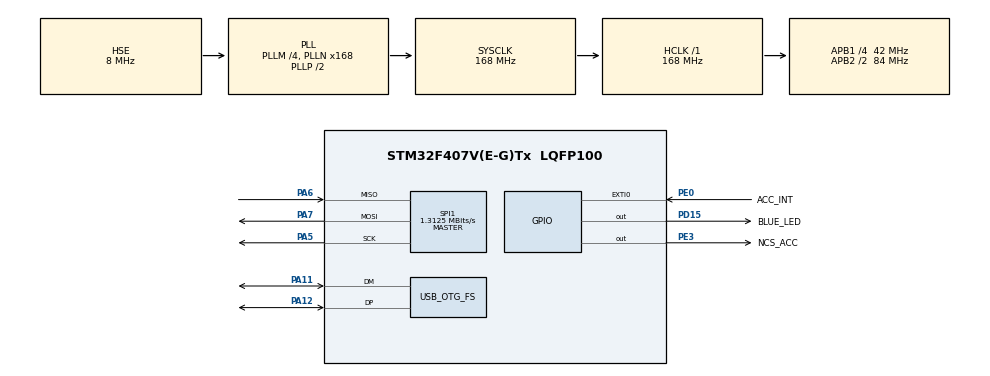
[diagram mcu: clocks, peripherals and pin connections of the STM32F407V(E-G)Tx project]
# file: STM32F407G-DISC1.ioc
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Dma.Request0=SPI1_RX
Dma.Request1=SPI1_TX
Dma.SPI1_RX.0.Direction=DMA_PERIPH_TO_MEMORY
Dma.SPI1_RX.0.FIFOMode=DMA_FIFOMODE_DISABLE
Dma.SPI1_RX.0.Instance=DMA2_Stream0
Dma.SPI1_RX.0.MemDataAlignment=DMA_MDATAALIGN_BYTE
Dma.SPI1_RX.0.MemInc=DMA_MINC_ENABLE
Dma.SPI1_RX.0.Mode=DMA_NORMAL
Dma.SPI1_RX.0.PeriphDataAlignment=DMA_PDATAALIGN_BYTE
Dma.SPI1_RX.0.PeriphInc=DMA_PINC_DISABLE
Dma.SPI1_RX.0.Priority=DMA_PRIORITY_HIGH
Dma.SPI1_TX.1.Direction=DMA_MEMORY_TO_PERIPH
Dma.SPI1_TX.1.FIFOMode=DMA_FIFOMODE_DISABLE
Dma.SPI1_TX.1.Instance=DMA2_Stream3
Dma.SPI1_TX.1.MemDataAlignment=DMA_MDATAALIGN_BYTE
Dma.SPI1_TX.1.MemInc=DMA_MINC_ENABLE
Dma.SPI1_TX.1.Mode=DMA_NORMAL
Dma.SPI1_TX.1.PeriphDataAlignment=DMA_PDATAALIGN_BYTE
Dma.SPI1_TX.1.PeriphInc=DMA_PINC_DISABLE
Dma.SPI1_TX.1.Priority=DMA_PRIORITY_HIGH
Mcu.Family=STM32F4
Mcu.Name=STM32F407V(E-G)Tx
Mcu.Package=LQFP100
NVIC.DMA2_Stream0_IRQn=true\:0\:0\:false\:false\:true\:false\:true
NVIC.DMA2_Stream3_IRQn=true\:0\:0\:false\:false\:true\:false\:true
NVIC.EXTI0_IRQn=true\:0\:0\:false\:false\:true\:true\:true
NVIC.OTG_FS_IRQn=true\:0\:0\:false\:false\:true\:false\:true
NVIC.PriorityGroup=NVIC_PRIORITYGROUP_4
PA11.Mode=Device_Only
PA11.Signal=USB_OTG_FS_DM
PA12.Mode=Device_Only
PA12.Signal=USB_OTG_FS_DP
PA13.Mode=Trace_Asynchronous_SW
PA13.Signal=SYS_JTMS-SWDIO
PA14.Mode=Trace_Asynchronous_SW
PA14.Signal=SYS_JTCK-SWCLK
PA5.Mode=Full_Duplex_Master
PA5.Signal=SPI1_SCK
PA6.Mode=Full_Duplex_Master
PA6.Signal=SPI1_MISO
PA7.Mode=Full_Duplex_Master
PA7.Signal=SPI1_MOSI
PB3.Mode=Trace_Asynchronous_SW
PB3.Signal=SYS_JTDO-SWO
PD15.GPIO_Label=BLUE_LED
PD15.Signal=GPIO_Output
PE0.GPIO_Label=ACC_INT
PE0.Signal=GPXTI0
PE3.GPIO_Label=NCS_ACC
PE3.Signal=GPIO_Output
PH0-OSC_IN.Mode=HSE-External-Oscillator
PH0-OSC_IN.Signal=RCC_OSC_IN
PH1-OSC_OUT.Mode=HSE-External-Oscillator
PH1-OSC_OUT.Signal=RCC_OSC_OUT
ProjectManager.HeapSize=0x200
ProjectManager.StackSize=0x400
ProjectManager.TargetToolchain=STM32CubeIDE
RCC.48MHZClocksFreq_Value=48000000
RCC.AHBFreq_Value=168000000
RCC.APB1CLKDivider=RCC_HCLK_DIV4
RCC.APB1Freq_Value=42000000
RCC.APB1TimFreq_Value=84000000
RCC.APB2CLKDivider=RCC_HCLK_DIV2
RCC.APB2Freq_Value=84000000
RCC.APB2TimFreq_Value=168000000
RCC.CortexFreq_Value=168000000
RCC.HCLKFreq_Value=168000000
RCC.HSE_VALUE=8000000
RCC.HSI_VALUE=16000000
RCC.LSE_VALUE=32768
RCC.PLLM=4
RCC.PLLN=168
RCC.PLLQ=7
RCC.SYSCLKFreq_VALUE=168000000
RCC.SYSCLKSource=RCC_SYSCLKSOURCE_PLLCLK
RCC.VCOOutputFreq_Value=336000000
SPI1.BaudRatePrescaler=SPI_BAUDRATEPRESCALER_64
SPI1.CLKPhase=SPI_PHASE_1EDGE
SPI1.CLKPolarity=SPI_POLARITY_LOW
SPI1.CalculateBaudRate=1.3125 MBits/s
SPI1.Direction=SPI_DIRECTION_2LINES
SPI1.Mode=SPI_MODE_MASTER
SPI1.VirtualType=VM_MASTER
USB_DEVICE.CLASS_NAME_FS=CDC
USB_DEVICE.VirtualMode-CDC_FS=Cdc
USB_DEVICE.VirtualModeFS=Cdc_FS
USB_OTG_FS.VirtualMode=Device_Only
VP_USB_DEVICE_VS_USB_DEVICE_CDC_FS.Mode=CDC_FS
board=custom

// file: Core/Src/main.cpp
/* USER CODE BEGIN Header */
/**
  ******************************************************************************
  * @file           : main.c
  * @brief          : This program is used to read the accelerometer data using
  * 				  polling mode, and send the data via USB
  ******************************************************************************
  *
  * Copyright (c) 2022 8E1XX.
  * This program is free software: you can redistribute it and/or modify
  * it under the terms of the GNU General Public License as published by
  * the Free Software Foundation, either version 3 of the License, or
  * (at your option) any later version.
  *
  * This program is distributed in the hope that it will be useful,
  * but WITHOUT ANY WARRANTY; without even the implied warranty of
  * MERCHANTABILITY or FITNESS FOR A PARTICULAR PURPOSE. See the
  * GNU General Public License for more details.
  * You should have received a copy of the GNU General Public License
  * along with this program.  If not, see http://www.gnu.org/licenses/
  *
  ******************************************************************************
  */
/* USER CODE END Header */
#include "main.h"
#include "usb_device.h"

/* USER CODE BEGIN Includes */
#include "LIS3DSH.h"
#include "usbd_cdc_if.h"
/* USER CODE END Includes */

SPI_HandleTypeDef hspi1;
DMA_HandleTypeDef hdma_spi1_rx;
DMA_HandleTypeDef hdma_spi1_tx;

/* USER CODE BEGIN PV */
LIS3DSH accel;
/* USER CODE END PV */

void SystemClock_Config(void);
static void MX_GPIO_Init(void);
static void MX_DMA_Init(void);
static void MX_SPI1_Init(void);

/* USER CODE BEGIN 0 */

void HAL_GPIO_EXTI_Callback(uint16_t GPIO_Pin) {
	// Check if the EXINT Source is Interrupt pin from Accelerometer
	if(GPIO_Pin == ACC_INT_Pin) {
    	accel.readDataDMA();
    }
}

void HAL_SPI_TxRxCpltCallback(SPI_HandleTypeDef *hspi) {
	// Check if the source is from SPI1
	if (hspi->Instance == SPI1) {
		accel.readDataDMAComplete();
	}
}

/* USER CODE END 0 */

int main(void)
{

  /* MCU Configuration--------------------------------------------------------*/

  /* Reset of all peripherals, Initializes the Flash interface and the Systick. */
  HAL_Init();

  /* Configure the system clock */
  SystemClock_Config();

  /* Initialize all configured peripherals */
  MX_GPIO_Init();
  MX_DMA_Init();
  MX_SPI1_Init();

  MX_USB_DEVICE_Init();
  /* USER CODE BEGIN 2 */
  char dataBuf [128];
  accel.init(&hspi1, NCS_ACC_GPIO_Port, NCS_ACC_Pin);
  /* USER CODE END 2 */

  /* Infinite loop */
  /* USER CODE BEGIN WHILE */
  while (1)
  {
	  sprintf(dataBuf, "%d %d %d\n", accel.getXRaw(),accel.getYRaw(),accel.getZRaw());
	  CDC_Transmit_FS((uint8_t *) dataBuf, strlen(dataBuf));
	  HAL_Delay(100);
    /* USER CODE END WHILE */

  }
}

void SystemClock_Config(void)
{
  RCC_OscInitTypeDef RCC_OscInitStruct = {0};
  RCC_ClkInitTypeDef RCC_ClkInitStruct = {0};

  /** Configure the main internal regulator output voltage
  */
  __HAL_RCC_PWR_CLK_ENABLE();
  __HAL_PWR_VOLTAGESCALING_CONFIG(PWR_REGULATOR_VOLTAGE_SCALE1);
  /** Initializes the RCC Oscillators according to the specified parameters
  * in the RCC_OscInitTypeDef structure.
  */
  RCC_OscInitStruct.OscillatorType = RCC_OSCILLATORTYPE_HSE;
  RCC_OscInitStruct.HSEState = RCC_HSE_ON;
  RCC_OscInitStruct.PLL.PLLState = RCC_PLL_ON;
  RCC_OscInitStruct.PLL.PLLSource = RCC_PLLSOURCE_HSE;
  RCC_OscInitStruct.PLL.PLLM = 4;
  RCC_OscInitStruct.PLL.PLLN = 168;
  RCC_OscInitStruct.PLL.PLLP = RCC_PLLP_DIV2;
  RCC_OscInitStruct.PLL.PLLQ = 7;
  if (HAL_RCC_OscConfig(&RCC_OscInitStruct) != HAL_OK)
  {
    Error_Handler();
  }
  /** Initializes the CPU, AHB and APB buses clocks
  */
  RCC_ClkInitStruct.ClockType = RCC_CLOCKTYPE_HCLK|RCC_CLOCKTYPE_SYSCLK
                              |RCC_CLOCKTYPE_PCLK1|RCC_CLOCKTYPE_PCLK2;
  RCC_ClkInitStruct.SYSCLKSource = RCC_SYSCLKSOURCE_PLLCLK;
  RCC_ClkInitStruct.AHBCLKDivider = RCC_SYSCLK_DIV1;
  RCC_ClkInitStruct.APB1CLKDivider = RCC_HCLK_DIV4;
  RCC_ClkInitStruct.APB2CLKDivider = RCC_HCLK_DIV2;

  if (HAL_RCC_ClockConfig(&RCC_ClkInitStruct, FLASH_LATENCY_5) != HAL_OK)
  {
    Error_Handler();
  }
}

static void MX_SPI1_Init(void)
{

  /* SPI1 parameter configuration*/
  hspi1.Instance = SPI1;
  hspi1.Init.Mode = SPI_MODE_MASTER;
  hspi1.Init.Direction = SPI_DIRECTION_2LINES;
  hspi1.Init.DataSize = SPI_DATASIZE_8BIT;
  hspi1.Init.CLKPolarity = SPI_POLARITY_LOW;
  hspi1.Init.CLKPhase = SPI_PHASE_1EDGE;
  hspi1.Init.NSS = SPI_NSS_SOFT;
  hspi1.Init.BaudRatePrescaler = SPI_BAUDRATEPRESCALER_64;
  hspi1.Init.FirstBit = SPI_FIRSTBIT_MSB;
  hspi1.Init.TIMode = SPI_TIMODE_DISABLE;
  hspi1.Init.CRCCalculation = SPI_CRCCALCULATION_DISABLE;
  hspi1.Init.CRCPolynomial = 10;
  if (HAL_SPI_Init(&hspi1) != HAL_OK)
  {
    Error_Handler();
  }

}

static void MX_DMA_Init(void)
{

  /* DMA controller clock enable */
  __HAL_RCC_DMA2_CLK_ENABLE();

  /* DMA interrupt init */
  /* DMA2_Stream0_IRQn interrupt configuration */
  HAL_NVIC_SetPriority(DMA2_Stream0_IRQn, 0, 0);
  HAL_NVIC_EnableIRQ(DMA2_Stream0_IRQn);
  /* DMA2_Stream3_IRQn interrupt configuration */
  HAL_NVIC_SetPriority(DMA2_Stream3_IRQn, 0, 0);
  HAL_NVIC_EnableIRQ(DMA2_Stream3_IRQn);

}

static void MX_GPIO_Init(void)
{
  GPIO_InitTypeDef GPIO_InitStruct = {0};

  /* GPIO Ports Clock Enable */
  __HAL_RCC_GPIOE_CLK_ENABLE();
  __HAL_RCC_GPIOH_CLK_ENABLE();
  __HAL_RCC_GPIOA_CLK_ENABLE();
  __HAL_RCC_GPIOD_CLK_ENABLE();
  __HAL_RCC_GPIOB_CLK_ENABLE();

  /*Configure GPIO pin Output Level */
  HAL_GPIO_WritePin(NCS_ACC_GPIO_Port, NCS_ACC_Pin, GPIO_PIN_RESET);

  /*Configure GPIO pin Output Level */
  HAL_GPIO_WritePin(BLUE_LED_GPIO_Port, BLUE_LED_Pin, GPIO_PIN_RESET);

  /*Configure GPIO pin : NCS_ACC_Pin */
  GPIO_InitStruct.Pin = NCS_ACC_Pin;
  GPIO_InitStruct.Mode = GPIO_MODE_OUTPUT_PP;
  GPIO_InitStruct.Pull = GPIO_NOPULL;
  GPIO_InitStruct.Speed = GPIO_SPEED_FREQ_LOW;
  HAL_GPIO_Init(NCS_ACC_GPIO_Port, &GPIO_InitStruct);

  /*Configure GPIO pin : BLUE_LED_Pin */
  GPIO_InitStruct.Pin = BLUE_LED_Pin;
  GPIO_InitStruct.Mode = GPIO_MODE_OUTPUT_PP;
  GPIO_InitStruct.Pull = GPIO_NOPULL;
  GPIO_InitStruct.Speed = GPIO_SPEED_FREQ_LOW;
  HAL_GPIO_Init(BLUE_LED_GPIO_Port, &GPIO_InitStruct);

  /*Configure GPIO pin : ACC_INT_Pin */
  GPIO_InitStruct.Pin = ACC_INT_Pin;
  GPIO_InitStruct.Mode = GPIO_MODE_IT_RISING;
  GPIO_InitStruct.Pull = GPIO_NOPULL;
  HAL_GPIO_Init(ACC_INT_GPIO_Port, &GPIO_InitStruct);

  /* EXTI interrupt init*/
  HAL_NVIC_SetPriority(EXTI0_IRQn, 0, 0);
  HAL_NVIC_EnableIRQ(EXTI0_IRQn);

}

void Error_Handler(void)
{
  __disable_irq();
  while (1)
  {
  }
}
